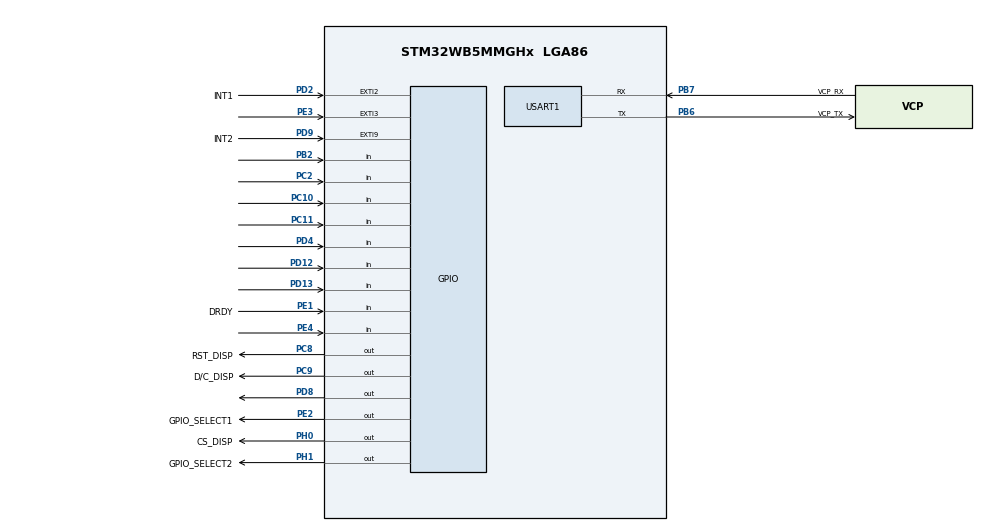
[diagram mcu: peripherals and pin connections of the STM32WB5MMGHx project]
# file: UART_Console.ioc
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Mcu.Family=STM32WB
Mcu.Name=STM32WB5MMGHx
Mcu.Package=LGA86
NVIC.PriorityGroup=NVIC_PRIORITYGROUP_4
PA0.Signal=ADCx_IN5
PA1.Signal=SPI1_SCK
PA10.Signal=I2C1_SDA
PA11.GPIO_Label=USB_N
PA11.Signal=USB_DM
PA12.GPIO_Label=USB_P
PA12.Signal=USB_DP
PA13.GPIO_Label=T_SWDIO
PA13.Signal=SYS_JTMS-SWDIO
PA14.GPIO_Label=T_SWCLK
PA14.Signal=SYS_JTCK-SWCLK
PA15.Signal=S_TIM2_CH1
PA2.Signal=ADCx_IN7
PA3.GPIO_Label=QSPI_BK_SCK
PA3.Signal=QUADSPI_CLK
PA4.Signal=SPI1_NSS
PA5.Signal=ADCx_IN10
PA6.Signal=LPUART1_CTS
PA7.Signal=SPI1_MOSI
PA8.GPIO_Label=SAI1_CK2
PA8.Signal=SAI1_CK2
PA9.GPIO_Label=SAI1_D2
PA9.Signal=SAI1_D2
PB10.Signal=S_TIM2_CH3
PB11.GPIO_Label=I2C3_SDA
PB11.Signal=I2C3_SDA
PB12.Signal=LPUART1_RTS
PB13.GPIO_Label=I2C3_SCL
PB13.Signal=I2C3_SCL
PB14.Signal=SPI2_MISO
PB15.Signal=SPI2_MOSI
PB2.Signal=GPIO_Input
PB3.GPIO_Label=T_SWO
PB3.Signal=SYS_JTDO-SWO
PB4.Signal=SPI1_MISO
PB5.GPIO_Label=LPUART1_TX_MCU
PB5.Signal=LPUART1_TX
PB6.GPIO_Label=VCP_TX
PB6.Mode=Asynchronous
PB6.Signal=USART1_TX
PB7.GPIO_Label=VCP_RX
PB7.Mode=Asynchronous
PB7.Signal=USART1_RX
PB8.Signal=I2C1_SCL
PB9.GPIO_Label=QSPI_BK_IO0
PB9.Signal=QUADSPI_BK1_IO0
PC0.GPIO_Label=LPUART1_RX_MCU
PC0.Signal=LPUART1_RX
PC1.Signal=ADCx_IN2
PC10.Signal=GPIO_Input
PC11.Signal=GPIO_Input
PC12.GPIO_Label=User-B1
PC12.Signal=SYS_WKUP3
PC13.GPIO_Label=User-B2
PC13.Signal=SYS_WKUP2
PC2.Signal=GPIO_Input
PC3.Signal=ADCx_IN4
PC4.Signal=ADCx_IN13
PC5.Signal=ADCx_IN14
PC6.GPIO_Label=TSC_G4_IO1
PC6.Signal=TSC_G4_IO1
PC7.GPIO_Label=TSC_G4_IO2
PC7.Signal=TSC_G4_IO2
PC8.GPIO_Label=RST_DISP
PC8.Signal=GPIO_Output
PC9.GPIO_Label=D/C_DISP
PC9.Signal=GPIO_Output
PD0.Signal=SPI2_NSS
PD1.Signal=SPI2_SCK
PD10.GPIO_Label=TSC_G6_IO1
PD10.Signal=TSC_G6_IO1
PD11.GPIO_Label=TSC_G6_IO2
PD11.Signal=TSC_G6_IO2
PD12.Signal=GPIO_Input
PD13.Signal=GPIO_Input
PD14.Signal=S_TIM1_CH1
PD15.Signal=S_TIM1_CH2
PD2.GPIO_Label=INT1
PD2.Signal=GPXTI2
PD3.GPIO_Label=QSPI_BK_NCS
PD3.Signal=QUADSPI_BK1_NCS
PD4.Signal=GPIO_Input
PD5.GPIO_Label=QSPI_BK_IO1
PD5.Signal=QUADSPI_BK1_IO1
PD6.GPIO_Label=QSPI_BK_IO2
PD6.Signal=QUADSPI_BK1_IO2
PD8.Signal=GPIO_Output
PD9.GPIO_Label=INT2
PD9.Signal=GPXTI9
PE0.Signal=S_TIM16_CH1
PE1.GPIO_Label=DRDY
PE1.Signal=GPIO_Input
PE2.GPIO_Label=GPIO_SELECT1
PE2.Signal=GPIO_Output
PE3.Signal=GPXTI3
PE4.Signal=GPIO_Input
PH0.GPIO_Label=CS_DISP
PH0.Signal=GPIO_Output
PH1.GPIO_Label=GPIO_SELECT2
PH1.Signal=GPIO_Output
ProjectManager.HeapSize=0x200
ProjectManager.StackSize=0x400
ProjectManager.TargetToolchain=STM32CubeIDE
RCC.APB3Freq_Value=16000000
RCC.HSE_VALUE=32000000
RCC.HSI48_VALUE=48000000
RCC.HSI_VALUE=16000000
RCC.VCOOutputFreq_Value=32000000
SH.ADCx_IN10.0=ADC1_IN10
SH.ADCx_IN13.0=ADC1_IN13
SH.ADCx_IN14.0=ADC1_IN14
SH.ADCx_IN2.0=ADC1_IN2
SH.ADCx_IN4.0=ADC1_IN4
SH.ADCx_IN5.0=ADC1_IN5
SH.ADCx_IN7.0=ADC1_IN7
SH.S_TIM16_CH1.0=TIM16_CH1
SH.S_TIM1_CH1.0=TIM1_CH1
SH.S_TIM1_CH2.0=TIM1_CH2
SH.S_TIM2_CH1.0=TIM2_CH1
SH.S_TIM2_CH3.0=TIM2_CH3
USART1.VirtualMode-Asynchronous=VM_ASYNC
board=STM32WB5MM-DK

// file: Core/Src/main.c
/* USER CODE BEGIN Header */
/**
  ******************************************************************************
  * @file           : main.c
  * @brief          : Main program body
  ******************************************************************************
  * @attention
  *
  * Copyright (c) 2022 STMicroelectronics.
  * All rights reserved.
  *
  * This software is licensed under terms that can be found in the LICENSE file
  * in the root directory of this software component.
  * If no LICENSE file comes with this software, it is provided AS-IS.
  *
  ******************************************************************************
  */
/* USER CODE END Header */
#include "main.h"

UART_HandleTypeDef huart1;

void SystemClock_Config(void);
void PeriphCommonClock_Config(void);
static void MX_GPIO_Init(void);
static void MX_USART1_UART_Init(void);
/* USER CODE BEGIN PFP */
#define PUTCHAR_PROTOTYPE int __io_putchar(int ch)
/* USER CODE END PFP */

int main(void)
{

  /* MCU Configuration--------------------------------------------------------*/

  /* Reset of all peripherals, Initializes the Flash interface and the Systick. */
  HAL_Init();

  /* Configure the system clock */
  SystemClock_Config();

/* Configure the peripherals common clocks */
  PeriphCommonClock_Config();

  /* Initialize all configured peripherals */
  MX_GPIO_Init();
  MX_USART1_UART_Init();

  /* Infinite loop */
  /* USER CODE BEGIN WHILE */
  while (1)
  {
	  printf("printf message TEST\n\r");
	  HAL_Delay(2000);
    /* USER CODE END WHILE */

  }
}

void SystemClock_Config(void)
{
  RCC_OscInitTypeDef RCC_OscInitStruct = {0};
  RCC_ClkInitTypeDef RCC_ClkInitStruct = {0};

  /** Configure the main internal regulator output voltage
  */
  __HAL_PWR_VOLTAGESCALING_CONFIG(PWR_REGULATOR_VOLTAGE_SCALE1);
  /** Initializes the RCC Oscillators according to the specified parameters
  * in the RCC_OscInitTypeDef structure.
  */
  RCC_OscInitStruct.OscillatorType = RCC_OSCILLATORTYPE_HSI|RCC_OSCILLATORTYPE_MSI;
  RCC_OscInitStruct.HSIState = RCC_HSI_ON;
  RCC_OscInitStruct.MSIState = RCC_MSI_ON;
  RCC_OscInitStruct.HSICalibrationValue = RCC_HSICALIBRATION_DEFAULT;
  RCC_OscInitStruct.MSICalibrationValue = RCC_MSICALIBRATION_DEFAULT;
  RCC_OscInitStruct.MSIClockRange = RCC_MSIRANGE_6;
  RCC_OscInitStruct.PLL.PLLState = RCC_PLL_NONE;
  if (HAL_RCC_OscConfig(&RCC_OscInitStruct) != HAL_OK)
  {
    Error_Handler();
  }
  /** Configure the SYSCLKSource, HCLK, PCLK1 and PCLK2 clocks dividers
  */
  RCC_ClkInitStruct.ClockType = RCC_CLOCKTYPE_HCLK4|RCC_CLOCKTYPE_HCLK2
                              |RCC_CLOCKTYPE_HCLK|RCC_CLOCKTYPE_SYSCLK
                              |RCC_CLOCKTYPE_PCLK1|RCC_CLOCKTYPE_PCLK2;
  RCC_ClkInitStruct.SYSCLKSource = RCC_SYSCLKSOURCE_MSI;
  RCC_ClkInitStruct.AHBCLKDivider = RCC_SYSCLK_DIV1;
  RCC_ClkInitStruct.APB1CLKDivider = RCC_HCLK_DIV1;
  RCC_ClkInitStruct.APB2CLKDivider = RCC_HCLK_DIV1;
  RCC_ClkInitStruct.AHBCLK2Divider = RCC_SYSCLK_DIV1;
  RCC_ClkInitStruct.AHBCLK4Divider = RCC_SYSCLK_DIV1;

  if (HAL_RCC_ClockConfig(&RCC_ClkInitStruct, FLASH_LATENCY_0) != HAL_OK)
  {
    Error_Handler();
  }
}

void PeriphCommonClock_Config(void)
{
  RCC_PeriphCLKInitTypeDef PeriphClkInitStruct = {0};

  /** Initializes the peripherals clock
  */
  PeriphClkInitStruct.PeriphClockSelection = RCC_PERIPHCLK_SMPS;
  PeriphClkInitStruct.SmpsClockSelection = RCC_SMPSCLKSOURCE_HSI;
  PeriphClkInitStruct.SmpsDivSelection = RCC_SMPSCLKDIV_RANGE1;

  if (HAL_RCCEx_PeriphCLKConfig(&PeriphClkInitStruct) != HAL_OK)
  {
    Error_Handler();
  }
}

static void MX_USART1_UART_Init(void)
{

  huart1.Instance = USART1;
  huart1.Init.BaudRate = 115200;
  huart1.Init.WordLength = UART_WORDLENGTH_8B;
  huart1.Init.StopBits = UART_STOPBITS_1;
  huart1.Init.Parity = UART_PARITY_NONE;
  huart1.Init.Mode = UART_MODE_TX_RX;
  huart1.Init.HwFlowCtl = UART_HWCONTROL_NONE;
  huart1.Init.OverSampling = UART_OVERSAMPLING_16;
  huart1.Init.OneBitSampling = UART_ONE_BIT_SAMPLE_DISABLE;
  huart1.Init.ClockPrescaler = UART_PRESCALER_DIV1;
  huart1.AdvancedInit.AdvFeatureInit = UART_ADVFEATURE_NO_INIT;
  if (HAL_UART_Init(&huart1) != HAL_OK)
  {
    Error_Handler();
  }
  if (HAL_UARTEx_SetTxFifoThreshold(&huart1, UART_TXFIFO_THRESHOLD_1_8) != HAL_OK)
  {
    Error_Handler();
  }
  if (HAL_UARTEx_SetRxFifoThreshold(&huart1, UART_RXFIFO_THRESHOLD_1_8) != HAL_OK)
  {
    Error_Handler();
  }
  if (HAL_UARTEx_DisableFifoMode(&huart1) != HAL_OK)
  {
    Error_Handler();
  }

}

static void MX_GPIO_Init(void)
{
  GPIO_InitTypeDef GPIO_InitStruct = {0};

  /* GPIO Ports Clock Enable */
  __HAL_RCC_GPIOA_CLK_ENABLE();
  __HAL_RCC_GPIOC_CLK_ENABLE();
  __HAL_RCC_GPIOB_CLK_ENABLE();
  __HAL_RCC_GPIOD_CLK_ENABLE();
  __HAL_RCC_GPIOE_CLK_ENABLE();
  __HAL_RCC_GPIOH_CLK_ENABLE();

  /*Configure GPIO pin Output Level */
  HAL_GPIO_WritePin(GPIOH, CS_DISP_Pin|GPIO_SELECT2_Pin, GPIO_PIN_RESET);

  /*Configure GPIO pin Output Level */
  HAL_GPIO_WritePin(GPIOC, D_C_DISP_Pin|RST_DISP_Pin, GPIO_PIN_RESET);

  /*Configure GPIO pin Output Level */
  HAL_GPIO_WritePin(GPIOD, GPIO_PIN_8, GPIO_PIN_RESET);

  /*Configure GPIO pin Output Level */
  HAL_GPIO_WritePin(GPIO_SELECT1_GPIO_Port, GPIO_SELECT1_Pin, GPIO_PIN_RESET);

  /*Configure GPIO pins : PA2 PA0 PA5 */
  GPIO_InitStruct.Pin = GPIO_PIN_2|GPIO_PIN_0|GPIO_PIN_5;
  GPIO_InitStruct.Mode = GPIO_MODE_ANALOG;
  GPIO_InitStruct.Pull = GPIO_NOPULL;
  HAL_GPIO_Init(GPIOA, &GPIO_InitStruct);

  /*Configure GPIO pins : PA1 PA7 PA4 */
  GPIO_InitStruct.Pin = GPIO_PIN_1|GPIO_PIN_7|GPIO_PIN_4;
  GPIO_InitStruct.Mode = GPIO_MODE_AF_PP;
  GPIO_InitStruct.Pull = GPIO_NOPULL;
  GPIO_InitStruct.Speed = GPIO_SPEED_FREQ_LOW;
  GPIO_InitStruct.Alternate = GPIO_AF5_SPI1;
  HAL_GPIO_Init(GPIOA, &GPIO_InitStruct);

  /*Configure GPIO pins : PC3 PC1 PC5 PC4 */
  GPIO_InitStruct.Pin = GPIO_PIN_3|GPIO_PIN_1|GPIO_PIN_5|GPIO_PIN_4;
  GPIO_InitStruct.Mode = GPIO_MODE_ANALOG;
  GPIO_InitStruct.Pull = GPIO_NOPULL;
  HAL_GPIO_Init(GPIOC, &GPIO_InitStruct);

  /*Configure GPIO pins : PC2 PC10 PC11 */
  GPIO_InitStruct.Pin = GPIO_PIN_2|GPIO_PIN_10|GPIO_PIN_11;
  GPIO_InitStruct.Mode = GPIO_MODE_INPUT;
  GPIO_InitStruct.Pull = GPIO_NOPULL;
  HAL_GPIO_Init(GPIOC, &GPIO_InitStruct);

  /*Configure GPIO pin : QSPI_BK_IO0_Pin */
  GPIO_InitStruct.Pin = QSPI_BK_IO0_Pin;
  GPIO_InitStruct.Mode = GPIO_MODE_AF_PP;
  GPIO_InitStruct.Pull = GPIO_NOPULL;
  GPIO_InitStruct.Speed = GPIO_SPEED_FREQ_LOW;
  GPIO_InitStruct.Alternate = GPIO_AF10_QUADSPI;
  HAL_GPIO_Init(QSPI_BK_IO0_GPIO_Port, &GPIO_InitStruct);

  /*Configure GPIO pin : LPUART1_RX_MCU_Pin */
  GPIO_InitStruct.Pin = LPUART1_RX_MCU_Pin;
  GPIO_InitStruct.Mode = GPIO_MODE_AF_PP;
  GPIO_InitStruct.Pull = GPIO_NOPULL;
  GPIO_InitStruct.Speed = GPIO_SPEED_FREQ_LOW;
  GPIO_InitStruct.Alternate = GPIO_AF8_LPUART1;
  HAL_GPIO_Init(LPUART1_RX_MCU_GPIO_Port, &GPIO_InitStruct);

  /*Configure GPIO pin : PB8 */
  GPIO_InitStruct.Pin = GPIO_PIN_8;
  GPIO_InitStruct.Mode = GPIO_MODE_AF_OD;
  GPIO_InitStruct.Pull = GPIO_NOPULL;
  GPIO_InitStruct.Speed = GPIO_SPEED_FREQ_LOW;
  GPIO_InitStruct.Alternate = GPIO_AF4_I2C1;
  HAL_GPIO_Init(GPIOB, &GPIO_InitStruct);

  /*Configure GPIO pins : LPUART1_TX_MCU_Pin PB12 */
  GPIO_InitStruct.Pin = LPUART1_TX_MCU_Pin|GPIO_PIN_12;
  GPIO_InitStruct.Mode = GPIO_MODE_AF_PP;
  GPIO_InitStruct.Pull = GPIO_NOPULL;
  GPIO_InitStruct.Speed = GPIO_SPEED_FREQ_LOW;
  GPIO_InitStruct.Alternate = GPIO_AF8_LPUART1;
  HAL_GPIO_Init(GPIOB, &GPIO_InitStruct);

  /*Configure GPIO pin : PB4 */
  GPIO_InitStruct.Pin = GPIO_PIN_4;
  GPIO_InitStruct.Mode = GPIO_MODE_AF_PP;
  GPIO_InitStruct.Pull = GPIO_NOPULL;
  GPIO_InitStruct.Speed = GPIO_SPEED_FREQ_LOW;
  GPIO_InitStruct.Alternate = GPIO_AF5_SPI1;
  HAL_GPIO_Init(GPIOB, &GPIO_InitStruct);

  /*Configure GPIO pin : PA15 */
  GPIO_InitStruct.Pin = GPIO_PIN_15;
  GPIO_InitStruct.Mode = GPIO_MODE_AF_PP;
  GPIO_InitStruct.Pull = GPIO_NOPULL;
  GPIO_InitStruct.Speed = GPIO_SPEED_FREQ_LOW;
  GPIO_InitStruct.Alternate = GPIO_AF1_TIM2;
  HAL_GPIO_Init(GPIOA, &GPIO_InitStruct);

  /*Configure GPIO pin : PA10 */
  GPIO_InitStruct.Pin = GPIO_PIN_10;
  GPIO_InitStruct.Mode = GPIO_MODE_AF_OD;
  GPIO_InitStruct.Pull = GPIO_NOPULL;
  GPIO_InitStruct.Speed = GPIO_SPEED_FREQ_LOW;
  GPIO_InitStruct.Alternate = GPIO_AF4_I2C1;
  HAL_GPIO_Init(GPIOA, &GPIO_InitStruct);

  /*Configure GPIO pins : USB_P_Pin USB_N_Pin */
  GPIO_InitStruct.Pin = USB_P_Pin|USB_N_Pin;
  GPIO_InitStruct.Mode = GPIO_MODE_AF_PP;
  GPIO_InitStruct.Pull = GPIO_NOPULL;
  GPIO_InitStruct.Speed = GPIO_SPEED_FREQ_LOW;
  GPIO_InitStruct.Alternate = GPIO_AF10_USB;
  HAL_GPIO_Init(GPIOA, &GPIO_InitStruct);

  /*Configure GPIO pins : PD0 PD1 */
  GPIO_InitStruct.Pin = GPIO_PIN_0|GPIO_PIN_1;
  GPIO_InitStruct.Mode = GPIO_MODE_AF_PP;
  GPIO_InitStruct.Pull = GPIO_NOPULL;
  GPIO_InitStruct.Speed = GPIO_SPEED_FREQ_LOW;
  GPIO_InitStruct.Alternate = GPIO_AF5_SPI2;
  HAL_GPIO_Init(GPIOD, &GPIO_InitStruct);

  /*Configure GPIO pins : I2C3_SCL_Pin I2C3_SDA_Pin */
  GPIO_InitStruct.Pin = I2C3_SCL_Pin|I2C3_SDA_Pin;
  GPIO_InitStruct.Mode = GPIO_MODE_AF_OD;
  GPIO_InitStruct.Pull = GPIO_NOPULL;
  GPIO_InitStruct.Speed = GPIO_SPEED_FREQ_LOW;
  GPIO_InitStruct.Alternate = GPIO_AF4_I2C3;
  HAL_GPIO_Init(GPIOB, &GPIO_InitStruct);

  /*Configure GPIO pins : TSC_G4_IO1_Pin TSC_G4_IO2_Pin */
  GPIO_InitStruct.Pin = TSC_G4_IO1_Pin|TSC_G4_IO2_Pin;
  GPIO_InitStruct.Mode = GPIO_MODE_AF_PP;
  GPIO_InitStruct.Pull = GPIO_NOPULL;
  GPIO_InitStruct.Speed = GPIO_SPEED_FREQ_LOW;
  GPIO_InitStruct.Alternate = GPIO_AF9_TSC;
  HAL_GPIO_Init(GPIOC, &GPIO_InitStruct);

  /*Configure GPIO pins : PB14 PB15 */
  GPIO_InitStruct.Pin = GPIO_PIN_14|GPIO_PIN_15;
  GPIO_InitStruct.Mode = GPIO_MODE_AF_PP;
  GPIO_InitStruct.Pull = GPIO_NOPULL;
  GPIO_InitStruct.Speed = GPIO_SPEED_FREQ_LOW;
  GPIO_InitStruct.Alternate = GPIO_AF5_SPI2;
  HAL_GPIO_Init(GPIOB, &GPIO_InitStruct);

  /*Configure GPIO pins : PE4 DRDY_Pin */
  GPIO_InitStruct.Pin = GPIO_PIN_4|DRDY_Pin;
  GPIO_InitStruct.Mode = GPIO_MODE_INPUT;
  GPIO_InitStruct.Pull = GPIO_NOPULL;
  HAL_GPIO_Init(GPIOE, &GPIO_InitStruct);

  /*Configure GPIO pin : PB10 */
  GPIO_InitStruct.Pin = GPIO_PIN_10;
  GPIO_InitStruct.Mode = GPIO_MODE_AF_PP;
  GPIO_InitStruct.Pull = GPIO_NOPULL;
  GPIO_InitStruct.Speed = GPIO_SPEED_FREQ_LOW;
  GPIO_InitStruct.Alternate = GPIO_AF1_TIM2;
  HAL_GPIO_Init(GPIOB, &GPIO_InitStruct);

  /*Configure GPIO pin : PB2 */
  GPIO_InitStruct.Pin = GPIO_PIN_2;
  GPIO_InitStruct.Mode = GPIO_MODE_INPUT;
  GPIO_InitStruct.Pull = GPIO_NOPULL;
  HAL_GPIO_Init(GPIOB, &GPIO_InitStruct);

  /*Configure GPIO pins : SAI1_CK2_Pin SAI1_D2_Pin */
  GPIO_InitStruct.Pin = SAI1_CK2_Pin|SAI1_D2_Pin;
  GPIO_InitStruct.Mode = GPIO_MODE_AF_PP;
  GPIO_InitStruct.Pull = GPIO_NOPULL;
  GPIO_InitStruct.Speed = GPIO_SPEED_FREQ_LOW;
  GPIO_InitStruct.Alternate = GPIO_AF3_SAI1;
  HAL_GPIO_Init(GPIOA, &GPIO_InitStruct);

  /*Configure GPIO pin : PA6 */
  GPIO_InitStruct.Pin = GPIO_PIN_6;
  GPIO_InitStruct.Mode = GPIO_MODE_AF_PP;
  GPIO_InitStruct.Pull = GPIO_NOPULL;
  GPIO_InitStruct.Speed = GPIO_SPEED_FREQ_LOW;
  GPIO_InitStruct.Alternate = GPIO_AF8_LPUART1;
  HAL_GPIO_Init(GPIOA, &GPIO_InitStruct);

  /*Configure GPIO pin : QSPI_BK_SCK_Pin */
  GPIO_InitStruct.Pin = QSPI_BK_SCK_Pin;
  GPIO_InitStruct.Mode = GPIO_MODE_AF_PP;
  GPIO_InitStruct.Pull = GPIO_NOPULL;
  GPIO_InitStruct.Speed = GPIO_SPEED_FREQ_LOW;
  GPIO_InitStruct.Alternate = GPIO_AF10_QUADSPI;
  HAL_GPIO_Init(QSPI_BK_SCK_GPIO_Port, &GPIO_InitStruct);

  /*Configure GPIO pins : CS_DISP_Pin GPIO_SELECT2_Pin */
  GPIO_InitStruct.Pin = CS_DISP_Pin|GPIO_SELECT2_Pin;
  GPIO_InitStruct.Mode = GPIO_MODE_OUTPUT_PP;
  GPIO_InitStruct.Pull = GPIO_NOPULL;
  GPIO_InitStruct.Speed = GPIO_SPEED_FREQ_LOW;
  HAL_GPIO_Init(GPIOH, &GPIO_InitStruct);

  /*Configure GPIO pins : PD14 PD15 */
  GPIO_InitStruct.Pin = GPIO_PIN_14|GPIO_PIN_15;
  GPIO_InitStruct.Mode = GPIO_MODE_AF_PP;
  GPIO_InitStruct.Pull = GPIO_NOPULL;
  GPIO_InitStruct.Speed = GPIO_SPEED_FREQ_LOW;
  GPIO_InitStruct.Alternate = GPIO_AF1_TIM1;
  HAL_GPIO_Init(GPIOD, &GPIO_InitStruct);

  /*Configure GPIO pins : PD13 PD12 PD4 */
  GPIO_InitStruct.Pin = GPIO_PIN_13|GPIO_PIN_12|GPIO_PIN_4;
  GPIO_InitStruct.Mode = GPIO_MODE_INPUT;
  GPIO_InitStruct.Pull = GPIO_NOPULL;
  HAL_GPIO_Init(GPIOD, &GPIO_InitStruct);

  /*Configure GPIO pins : INT1_Pin INT2_Pin */
  GPIO_InitStruct.Pin = INT1_Pin|INT2_Pin;
  GPIO_InitStruct.Mode = GPIO_MODE_IT_RISING;
  GPIO_InitStruct.Pull = GPIO_NOPULL;
  HAL_GPIO_Init(GPIOD, &GPIO_InitStruct);

  /*Configure GPIO pins : D_C_DISP_Pin RST_DISP_Pin */
  GPIO_InitStruct.Pin = D_C_DISP_Pin|RST_DISP_Pin;
  GPIO_InitStruct.Mode = GPIO_MODE_OUTPUT_PP;
  GPIO_InitStruct.Pull = GPIO_NOPULL;
  GPIO_InitStruct.Speed = GPIO_SPEED_FREQ_LOW;
  HAL_GPIO_Init(GPIOC, &GPIO_InitStruct);

  /*Configure GPIO pins : QSPI_BK_NCS_Pin QSPI_BK_IO1_Pin QSPI_BK_IO2_Pin */
  GPIO_InitStruct.Pin = QSPI_BK_NCS_Pin|QSPI_BK_IO1_Pin|QSPI_BK_IO2_Pin;
  GPIO_InitStruct.Mode = GPIO_MODE_AF_PP;
  GPIO_InitStruct.Pull = GPIO_NOPULL;
  GPIO_InitStruct.Speed = GPIO_SPEED_FREQ_LOW;
  GPIO_InitStruct.Alternate = GPIO_AF10_QUADSPI;
  HAL_GPIO_Init(GPIOD, &GPIO_InitStruct);

  /*Configure GPIO pin : PE3 */
  GPIO_InitStruct.Pin = GPIO_PIN_3;
  GPIO_InitStruct.Mode = GPIO_MODE_IT_RISING;
  GPIO_InitStruct.Pull = GPIO_NOPULL;
  HAL_GPIO_Init(GPIOE, &GPIO_InitStruct);

  /*Configure GPIO pin : PD8 */
  GPIO_InitStruct.Pin = GPIO_PIN_8;
  GPIO_InitStruct.Mode = GPIO_MODE_OUTPUT_PP;
  GPIO_InitStruct.Pull = GPIO_NOPULL;
  GPIO_InitStruct.Speed = GPIO_SPEED_FREQ_LOW;
  HAL_GPIO_Init(GPIOD, &GPIO_InitStruct);

  /*Configure GPIO pins : TSC_G6_IO1_Pin TSC_G6_IO2_Pin */
  GPIO_InitStruct.Pin = TSC_G6_IO1_Pin|TSC_G6_IO2_Pin;
  GPIO_InitStruct.Mode = GPIO_MODE_AF_PP;
  GPIO_InitStruct.Pull = GPIO_NOPULL;
  GPIO_InitStruct.Speed = GPIO_SPEED_FREQ_LOW;
  GPIO_InitStruct.Alternate = GPIO_AF9_TSC;
  HAL_GPIO_Init(GPIOD, &GPIO_InitStruct);

  /*Configure GPIO pin : GPIO_SELECT1_Pin */
  GPIO_InitStruct.Pin = GPIO_SELECT1_Pin;
  GPIO_InitStruct.Mode = GPIO_MODE_OUTPUT_PP;
  GPIO_InitStruct.Pull = GPIO_NOPULL;
  GPIO_InitStruct.Speed = GPIO_SPEED_FREQ_LOW;
  HAL_GPIO_Init(GPIO_SELECT1_GPIO_Port, &GPIO_InitStruct);

  /*Configure GPIO pin : PE0 */
  GPIO_InitStruct.Pin = GPIO_PIN_0;
  GPIO_InitStruct.Mode = GPIO_MODE_AF_PP;
  GPIO_InitStruct.Pull = GPIO_NOPULL;
  GPIO_InitStruct.Speed = GPIO_SPEED_FREQ_LOW;
  GPIO_InitStruct.Alternate = GPIO_AF14_TIM16;
  HAL_GPIO_Init(GPIOE, &GPIO_InitStruct);

}

/* USER CODE BEGIN 4 */
/**
 * @brief  Retargets the C library printf function to the USART.
 * @param  None
 * @retval None
 */
PUTCHAR_PROTOTYPE
{
	/* Place your implementation of fputc here */
	/* e.g. write a character to the USART1 and Loop until the end of transmission */
	HAL_UART_Transmit(&huart1, (uint8_t *)&ch, 1, 0xFFFF);

	return ch;
}
/* USER CODE END 4 */

void Error_Handler(void)
{
  __disable_irq();
  while (1)
  {
  }
}
